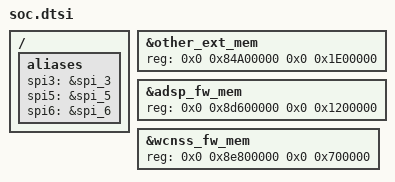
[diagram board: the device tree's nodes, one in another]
/* msm8953-ysl.dtsi */

/* msm8953.dtsi */
&other_ext_mem {
	reg = <0x0 0x84A00000 0x0 0x1E00000>;
};
&adsp_fw_mem {
	reg = <0x0 0x8d600000 0x0 0x1200000>;
};
&wcnss_fw_mem {
	reg = <0x0 0x8e800000 0x0 0x700000>;
};

/ {
	aliases {
		spi3 = &spi_3;
		spi5 = &spi_5;
        spi6 = &spi_6;
	};
};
